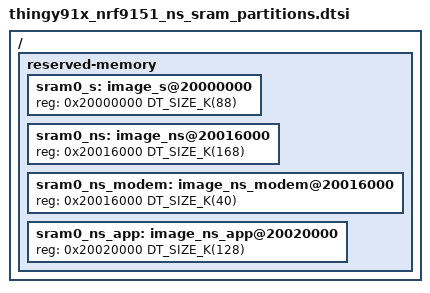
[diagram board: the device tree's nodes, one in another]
/*
 * Copyright (c) 2024 Nordic Semiconductor
 * SPDX-License-Identifier: LicenseRef-Nordic-5-Clause
 */

/ {
	/*
	 * SRAM memory planning for nRF9151 with ARM TrustZone-M support
	 * - Lowest 88 kB SRAM allocated to Secure image (sram0_s)
	 * - Upper 168 kB SRAM allocated to Non-Secure image (sram0_ns)
	 * Of the memory allocated to the Non-Secure image:
	 * - 40 kB SRAM reserved for modem library (sram0_ns_modem)
	 * - 128 kB allocated to the application (sram0_ns_app)
	 */
	reserved-memory {
		#address-cells = <1>;
		#size-cells = <1>;
		ranges;

		sram0_s: image_s@20000000 {
			/* Secure image memory */
			reg = <0x20000000 DT_SIZE_K(88)>;
		};

		sram0_ns: image_ns@20016000 {
			/* Non-Secure image memory */
			reg = <0x20016000 DT_SIZE_K(168)>;
		};

		sram0_ns_modem: image_ns_modem@20016000 {
			/* Modem (shared) memory */
			reg = <0x20016000 DT_SIZE_K(40)>;
		};

		sram0_ns_app: image_ns_app@20020000 {
			/* Non-Secure application memory */
			reg = <0x20020000 DT_SIZE_K(128)>;
		};
	};
};
